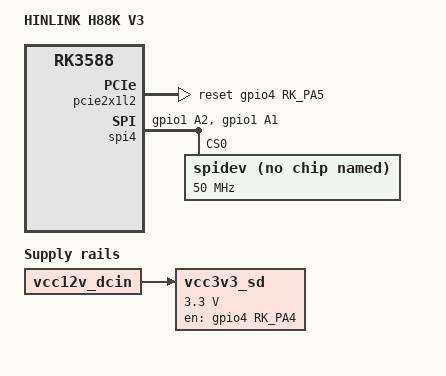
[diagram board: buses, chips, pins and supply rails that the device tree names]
// SPDX-License-Identifier: (GPL-2.0+ OR MIT)
/*
 * Copyright (c) 2023 iStoreOS
 * (https://www.istoreos.com)
 *
 * Copyright (c) 2022 Rockchip Electronics Co., Ltd.
 *
 */

/dts-v1/;

#include "rk3588-hinlink.dtsi"

/ {
	model = "HINLINK H88K V3";
	compatible = "hinlink,h88k-v3", "rockchip,rk3588";

	vcc3v3_sd: vcc3v3-sd-regulator {
		compatible = "regulator-fixed";
		enable-active-high;
		regulator-always-on;
		regulator-boot-on;
		gpios = <&gpio4 RK_PA4 GPIO_ACTIVE_HIGH>;
		regulator-min-microvolt = <3300000>;
		regulator-max-microvolt = <3300000>;
		regulator-name = "vcc3v3_sd";
		vin-supply = <&vcc12v_dcin>;
	};
};

// combphy0_ps
&pcie2x1l2 {
	// rtl8125
	reset-gpios = <&gpio4 RK_PA5 GPIO_ACTIVE_HIGH>;
	status = "okay";
};

// lcd
&spi4 {
	status = "okay";
	pinctrl-0 = <&spi4m2_cs0 &spi4m2_out_pins>;
	spidev@0 {
		compatible = "rockchip,spidev";
		reg = <0>;
		spi-max-frequency = <50000000>;
		status = "okay";
		pinctrl-names = "default";
		pinctrl-0 = <&spi_lcd_pins>;
	};
};

&pinctrl {
	spi4 {
		/omit-if-no-ref/
		spi4m2_out_pins: spi4m2-out-pins {
			rockchip,pins =
				/* spi4_clk_m2 */
				<1 RK_PA2 8 &pcfg_pull_up_drv_level_6>,
				/* spi4_mosi_m2 */
				<1 RK_PA1 8 &pcfg_pull_up_drv_level_6>;
		};
	};
	lcd {
		/omit-if-no-ref/
		spi_lcd_pins: spi-lcd-pins {
			rockchip,pins =
				<1 RK_PA4 RK_FUNC_GPIO &pcfg_pull_none>;
		};
	};
};
